# PIC32MZ1025W104132 register map
Vendor: Microchip
Registers are 32-bit, read-write, no defined reset value unless marked. A register's access mark holds for its fields unless they carry their own. Addresses are absolute, and some are shared; only a register's first bit layout is shown; [hi:lo] are bit positions; {n}, {i} and the like mark numbered series; 'fields as' and 'values as' point back to an identical list.

## CONFIG — Configuration words, addresses in PhysicalSpace
0x1FC55E88 AFUSERID reset 0xFFFF
  [15:0] USERID
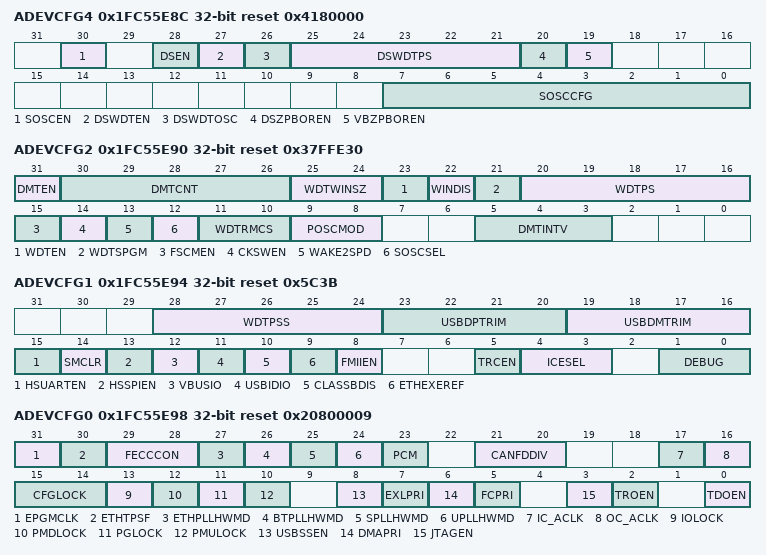
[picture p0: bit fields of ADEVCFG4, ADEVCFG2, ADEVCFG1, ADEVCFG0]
0x1FC55E8C ADEVCFG4 reset 0x4180000
  [30] SOSCEN — Secondary Oscillator Enable
    1=ON (Enabled); 0=OFF (Disabled)
  [28] DSEN — Deep Sleep Enable
    1=ON (Enabled); 0=OFF (Disabled)
  [27] DSWDTEN — Deep Sleep Watchdog Timer Enable
    1=ON (Enabled); 0=OFF (Disabled)
  [26] DSWDTOSC — Deep Sleep WDT Reference Clock Selection
    0=SOSC (Select SOSC as DSWDT Reference Clock); 1=LPRC (Select LPRC as DSWDT Reference Clock)
  [25:21] DSWDTPS — Deep Sleep Watchdog Timer Postscaler
    {v}=DSPS{v+1} (1:2^{v+5}) (v=0..31)
  [20] DSZPBOREN — Deep Sleep Zero-Power BOR Enable bit
    1=ON (Enabled); 0=OFF (Disabled)
  [19] VBZPBOREN — VBAT Zero-Power BOR Enable bit
    1=ON (Enabled); 0=OFF (Disabled)
  [7:0] SOSCCFG — SOSC Configuration Bits
0x1FC55E90 ADEVCFG2 reset 0x37FFE30
  [31] DMTEN — Deadman Timer Enable
    1=ON (Deadman Timer is enabled); 0=OFF (Deadman Timer is disabled)
  [30:26] DMTCNT — Dead Man Timer Count Select bits
    0=DMT8 (2^8 (256)); 1=DMT9 (2^9 (512)); 2=DMT10 (2^10 (1024)); 3=DMT11 (2^11 (2048)); 4=DMT12 (2^12 (4096)); 5=DMT13 (2^13 (8192)); 6=DMT14 (2^14 (16384)); 7=DMT15 (2^15 (32768)); 8=DMT16 (2^16 (65536)); 9=DMT17 (2^17 (131072)); 10=DMT18 (2^18 (262144)); 11=DMT19 (2^19 (524288)); 12=DMT20 (2^20 (1048576)); 13=DMT21 (2^21 (2097152)); 14=DMT22 (2^22 (4194304)); 15=DMT23 (2^23 (8388608)); 16=DMT24 (2^24 (16777216)); 17=DMT25 (2^25 (33554432)); 18=DMT26 (2^26 (67108864)); 19=DMT27 (2^27 (134217728)); 20=DMT28 (2^28 (268435456)); 21=DMT29 (2^29 (536870912)); 22=DMT30 (2^30 (1073741824)); 23=DMT31 (2^31 (2147483648))
  [25:24] WDTWINSZ — Watchdog Timer Window Size
    3=WINSZ_25 (Window size is 25%); 2=WINSZ_37 (Window size is 37.5%); 1=WINSZ_50 (Window size is 50%); 0=WINSZ_75 (Window size is 75%)
  [23] WDTEN — Watchdog Timer Enable bit
    0=OFF (WDT Disabled); 1=ON (WDT Enabled)
  [22] WINDIS — Watchdog Timer Window Mode
    1=NORMAL (Watchdog Timer is in non-Window mode); 0=WINDOW (Watchdog Timer is in Window mode)
  [21] WDTSPGM — Watchdog Timer Stop During Flash Programming
    0=RUN (WDT runs during Flash programming); 1=STOP (WDT stops during Flash programming)
  [20:16] WDTPS — Run mode watchdog timer postscaler
    0=PS1 (1:1); 1=PS2 (1:2); 2=PS4 (1:4); 3=PS8 (1:8); 4=PS16 (1:16); 5=PS32 (1:32); 6=PS64 (1:64); 7=PS128 (1:128); 8=PS256 (1:256); 9=PS512 (1:512); 10=PS1024 (1:1024); 11=PS2048 (1:2048); 12=PS4096 (1:4096); 13=PS8192 (1:8192); 14=PS16384 (1:16384); 15=PS32768 (1:32768); 0b1x000=PS65536 (1:65536); 0b1x001=PS131072 (1:131072); 0b1x010=PS262144 (1:262144); 0b1x011=PS524288 (1:524288); 0b1x1xx=PS1048576 (1:1048576)
  [15] FSCMEN — Fail safe clock monitor enabled
    1=ON (FSCM Enabled); 0=OFF (FSCM Disabled)
  [14] CKSWEN — software clock switching enable
    1=ON (Software Clock Switching Enabled); 0=OFF (Software Clock Switching Disabled)
  [13] WAKE2SPD — 2 speed startup control for sleep mode
    1=ON (the sys_clk will be from FRC until the selected clock is ready on wakeup); 0=OFF (the sys_clk will be from the selected clock on wakeup)
  [12] SOSCSEL — Secondary Oscillator selection
    1=CRYSTAL (Crystal (SOSCI/SOSCO) mode); 0=DIGITAL (Digital (SCLKI) mode)
  [11:10] WDTRMCS — WDT Run mode clock selection
    3=LPRC (LPRC used as WDT run mode clock source); 0=PBCLK (Peripheral bus clock used as WDT run mode clock source)
  [9:8] POSCMOD — Primary Oscillator Configuration
    3=OFF (Primary oscillator disabled); 2=HS (HS oscillator mode selected)
  [5:3] DMTINTV — DMT Count Window Interval
    0=WIN_0 (Window/Interval value is zero); 1=WIN_1_2 (Window/Interval value is 1/2 counter value); 2=WIN_3_4 (Window/Interval value is 3/4 counter value); 3=WIN_7_8 (Window/Interval value is 7/8 counter value); 4=WIN_15_16 (Window/Interval value is 15/16 counter value); 5=WIN_31_32 (Window/Interval value is 31/32 counter value); 6=WIN_63_64 (Window/Interval value is 63/64 counter value); 7=WIN_127_128 (Window/Interval value is 127/128 counter value)
0x1FC55E94 ADEVCFG1 reset 0x5C3B
  [28:24] WDTPSS — Watchdog Timer Post-scale Select Sleep bits
    20=PSS1048576 (1:1048576); 19=PSS524288 (1:524288); 18=PSS262144 (1:262144); 17=PSS131072 (1:131072); 16=PSS65536 (1:65536); 15=PSS32768 (1:32768); 14=PSS16384 (1:16384); 13=PSS8192 (1:8192); 12=PSS4096 (1:4096); 11=PSS2048 (1:2048); 10=PSS1024 (1:1024); 9=PSS512 (1:512); 8=PSS256 (1:256); 7=PSS128 (1:128); 6=PSS64 (1:64); 5=PSS32 (1:32); 4=PSS16 (1:16); 3=PSS8 (1:8); 2=PSS4 (1:4); 1=PSS2 (1:2); 0=PSS1 (1:1)
  [23:20] USBDPTRIM — USB DP Rise/Fall Trim fuse bits
  [19:16] USBDMTRIM — USB DM Rise/Fall Trim fuse bits
  [15] HSUARTEN — UART1 High Speed Mode Enable
    1=ON (UART1 is driven from/to dedicated pins, resulting in the highest possible maximum baud rate); 0=OFF (UART1 is driven through PPS (I/O remap), resulting in a lower maximum baud rate)
  [14] SMCLR — Selects CRU handling of MCLR Control
    1=MCLR_NORM (Legacy mode (system clear does not reset all state of device)); 0=MCLR_POR (MCLR causes a faux POR)
  [13] HSSPIEN — SPI1 High Speed Mode Enable
    1=ON (SPI1 is driven from/to dedicated pins, resulting in the highest interface speed); 0=OFF (SPI1 is driven through PPS (I/O remap), resulting in a lower interface speed)
  [12] VBUSIO — USB VBUS_ON Selection bit
    1=ON (VBUS_ON pin is controlled by the USB Module); 0=OFF (VBUS_ON pin is controlled by the Port Function)
  [11] USBIDIO — USB USBID Selection bit
    1=ON (USBID pin is controlled by the USB Module); 0=OFF (USBID pin is controlled by the Port Function)
  [10] CLASSBDIS — Disable CLASSB Device Functionality
    0=ENABLE (CLASSB functions enabled); 1=DISABLE (CLASSB functions disabled)
  [9] ETHEXEREF — Exclusive Ethernet PYHY reference clock Enable
    1=ON (PHY reference clock is made available on ETH EXCLK out); 0=OFF (ETH CLK out will be used as PHY reference clock if needed)
  [8] FMIIEN — Ethernet RMII/MII Enable
    0=OFF (RMII Enabled); 1=ON (MII Enabled)
  [5] TRCEN — Trace Enable
    1=ON (Trace features in the CPU are enabled); 0=OFF (Trace features in the CPU are disabled)
  [4:3] ICESEL — EMUC/EMUD Communication Channel Select
    3=ICS_PGx1 (ICE EMUC1/EMUD1 pins are shared with PGC1/PGD1); 2=ICS_PGx2 (ICE EMUC2/EMUD2 pins are shared with PGC2/PGD2); 1=ICS_PGx3 (ICE EMUC3/EMUD3 pins are shared with PGC3/PGD3); 0=ICS_PGx4 (ICE EMUC4/EMUD4 pins are shared with PGC4/PGD4)
  [1:0] DEBUG — Background Debugger Access Selection
    3=JTAG (4-wire JTAG I/F Enabled - EMUC/EMUD Disabled - ICD Module Disabled); 2=JTAG_ICD (4-wire JTAG I/F Enabled - EMUC/EMUD Disabled - ICD Module Enabled); 1=EMUC (EMUC/EMUD Enabled - 4-wire JTAG I/F Disabled - ICD Module Disabled); 0=EMUC_ICD (EMUC/EMUD Enabled - 4-wire JTAG I/F Disabled - ICD Module Enabled)
0x1FC55E98 ADEVCFG0 reset 0x20800009
  [31] EPGMCLK — External Programming Clock enable
    1=TSTFRC (In ICSP (TMOD0) mode, enable the FRC clock to be driven by the TSTFRC Pin Function); 0=FRC (In ICSP (TMOD0) mode, the FRC clock is always driven by the FRC oscillator)
  [30] ETHTPSF — Ethernet Tx SOF control for CTR measurements
    1=TPSF (TPSF is enabled in CTR measurement); 0=RPSF (RPSF is enabled in CTR measurement)
  [29:28] FECCCON — Dynamic Flash ECC Configuration
    0=ON (Flash ECC is enabled); 1=DYNAMIC (Dynamic Flash ECC is enabled); 2=OFF (ECC and Dynamic ECC are disabled)
  [27] ETHPLLHWMD — Ethernet PLL HW Control Mode for power down and RESET
    1=ON (ETHPLL PWDN and RESET are generated by HW); 0=OFF (ETHPLL PWDN and RESET are generated by SW using corresponding PLLCON register bits)
  [26] BTPLLHWMD — BTPLL HW Control Mode for power down and RESET
    1=ON (BTPLL PWDN and RESET are generated by HW); 0=OFF (BTPLL PWDN and RESET are generated by SW using corresponding PLLCON register bits)
  [25] SPLLHWMD — SPLL HW Control Mode for power down and RESET
    1=ON (SPLL PWDN and RESET are generated by HW); 0=OFF (SPLL PWDN and RESET are generated by SW using corresponding PLLCON register bits)
  [24] UPLLHWMD — UPLL HW Control Mode for power down and RESET
    1=ON (UPLL PWDN and RESET are generated by HW); 0=OFF (UPLL PWDN and RESET are generated by SW using corresponding PLLCON register bits)
  [23] PCM — P-Cache cache-ability control
    0=CPU (PCHE cache-ability is controlled by CPU); 1=SFR (PCHE cache-ability is controled by SFR)
  [21:20] CANFDDIV — CAN-FD divider control
  [17] IC_ACLK — ICAP Alternate Clock Selection
    1=ICAP_ALT_TMR (ICAP module use an alternative TMR pair as their timebase clock); 0=ICAP_TMR2_TMR3 (All ICAP Modules use TMR2/TMR3 as their timebase clock)
  [16] OC_ACLK — OCMP Alternate Clock Selection
    1=OCMP_ALT_TMR (OCMP module use an alternative TMR pair as their timebase clock); 0=OCMP_TMR2_TMR3 (All OCMP Modules use TMR2/TMR3 as their timebase clock)
  [15:14] CFGLOCK — Configuration Register Lock
    0=OFF (All NVR memory self-writes, BCFG0 and System Config registers, are not locked and can be written - CFGLOCK value can be changed); 2=ON_W (All NVR memory self-writes, BCFG0 and System Config registers, are locked and can not be written - CFGLOCK value can be changed); 3=ON (All NVR memory self-writes, BCFG0 and System Config registers, are locked and can not be written - CFGLOCK value can not be changed)
  [13] IOLOCK
    1=ON (IO Remap SFR bits are locked and cannot be modified); 0=OFF (IO Remap SFR are not locked and can be modified)
  [12] PMDLOCK — Peripheral Module Disable (PMD) LOCK
    1=ON (PMDx SFR bits are locked and cannot be modified); 0=OFF (PMDx SFR bits are not locked and can be modified)
  [11] PGLOCK — Permission Group LOCK
    1=ON (CFGPG SFR bits are locked and cannot be modified); 0=OFF (CFGPG SFR bits are not locked and can be modified)
  [10] PMULOCK — PMU Controller Register LOCK
    1=ON (PMU SFR bits are locked and cannot be modified); 0=OFF (PMU SFR bits are not locked and can be modified)
  [8] USBSSEN — USB Suspend Sleep Enable
    1=ON (USB FREF clock is shut down when suspend mode is active); 0=OFF (USB FREF clock continues to run when suspend mode is active)
  [7] EXLPRI — CPU RAM access priority
    1=HIGH (CPU gets high priority access to RAM); 0=LRSA (CPU gets least recently used arbitration to RAM)
  [6] DMAPRI — DMA RAM access priority
    1=HIGH (DMA gets High Priority access to SRAM); 0=LRSA (DMA gets least recently used arbitration to RAM)
  [5] FCPRI — Flash controller RAMa ccess priority
    1=HIGH (flash gets higher priority access to RAM); 0=LRSA (flash gets least recently used arbitration to RAM)
  [3] JTAGEN — JTAG control bit
    1=ON (JTAG port enabled); 0=OFF (JTAG port disabled)
  [2] TROEN — Trace clock control bit
    1=ON (Start Trace Clock and enable Trace Outputs (Trace Probe must be present)); 0=OFF (Stop Trace Clock and disable Trace Outputs)
  [0] TDOEN — TDO control for 2 wire JTAG protocol
    1=ON (2-wire JTAG protocol uses TDO); 0=OFF (2-wire JTAG protocol does not use TDO)
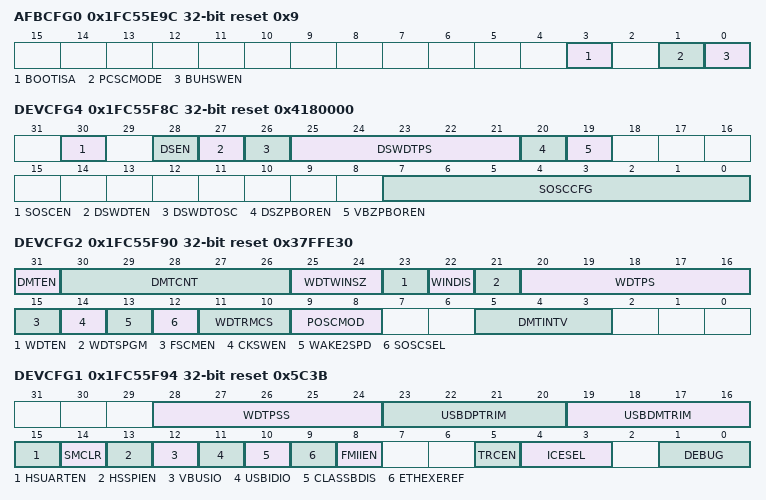
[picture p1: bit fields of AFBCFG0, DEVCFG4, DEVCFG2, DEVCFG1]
0x1FC55E9C AFBCFG0 reset 0x9 — FBCFG0
  [3] BOOTISA — Boot and exception code mode
    1=MIPS32 (Boot code and Exception code is MIPS32); 0=MICROMIPS (Boot code and Exception code is microMIPS)
  [1] PCSCMODE — PCache Single cache Mode
    1=SINGLE (PCHE ICache Only.CPU Instructions (code, data) go to PCHE ONLY.); 0=DUAL (PCHE ICache and DCache. CPU opcodes go to PCEHE ICache port and data goes to PCHE)
  [0] BUHSWEN — Buck mode switching control
    1=ON (Buck mode is switched in HW at POR before CPU is allowed to boot); 0=OFF (Buck switching is disabled in HW at POR. Enable from SW)
0x1FC55EBC AFCPN0 reset 0xFFFFFFFF
  [28] CP — Code Protect
    0=ON (Code protection enabled); 1=OFF (Code protection disabled)
0x1FC55F88 FUSERID reset 0xFFFF
  [15:0] USERID
0x1FC55F8C DEVCFG4 reset 0x4180000
  fields as ADEVCFG4
0x1FC55F90 DEVCFG2 reset 0x37FFE30
  fields as ADEVCFG2
0x1FC55F94 DEVCFG1 reset 0x5C3B
  fields as ADEVCFG1
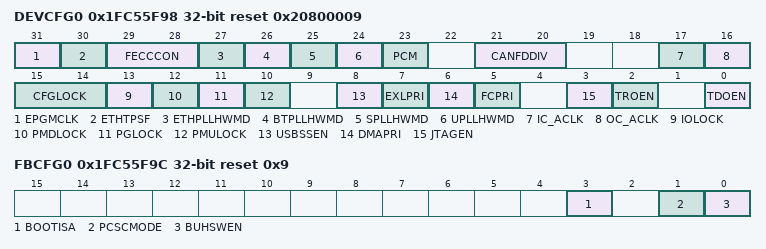
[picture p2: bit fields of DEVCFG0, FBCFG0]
0x1FC55F98 DEVCFG0 reset 0x20800009
  fields as ADEVCFG0
0x1FC55F9C FBCFG0 reset 0x9
  fields as AFBCFG0
0x1FC55FBC FCPN0 reset 0xFFFFFFFF
  fields as AFCPN0
0x1FC55FDC FSIGN0 reset 0x0
  [31] SIGN
    0=VALID (Config signature is valid); 1=INVALID (Config value is invalid)
